# f28002x_dcsm_common_regs register map
Vendor: Texas Instruments
Peripheral module from a debugger description file (folder C2000).
Address unit: 16 bits
Registers are 32-bit, read-write, no defined reset value unless marked. A register's access mark holds for its fields unless they carry their own. Offsets are as the file gives them; lines under a group give offsets from that group; [hi:lo] are bit positions; {n}, {i} and the like mark numbered series; 'fields as' and 'values as' point back to an identical list; <NAME> marks a mode.

## DCSM_COMMON_REGS — DCSM COMMON Registers
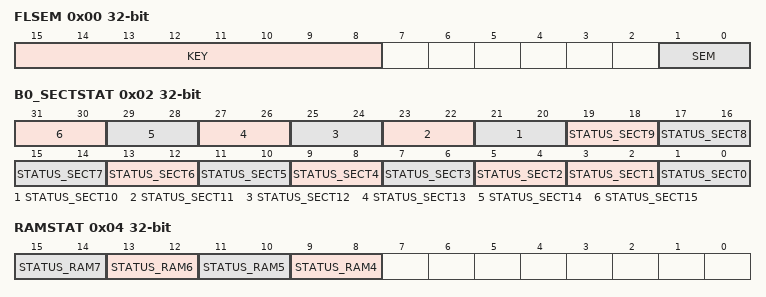
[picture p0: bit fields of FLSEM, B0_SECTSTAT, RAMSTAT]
0x00 FLSEM — Flash Wrapper Semaphore Register
  [15:8] KEY — Semaphore Key
  [1:0] SEM — Flash Semaphore Bit
0x02 B0_SECTSTAT ro — Flash BANK0 Sectors Status Register
  [2n+1:2n] STATUS_SECT{n} (n=9..15) — Zone Status Flash BANK0 Sector {n}
  [17:16] STATUS_SECT8 — Zone Status Flash BANK0 sector 8
  [2n+1:2n] STATUS_SECT{n} (n=2..7) — Zone Status Flash BANK0 Sector {n}
  [3:2] STATUS_SECT1 — Zone Status Flash BANK0 sector 1
  [1:0] STATUS_SECT0 — Zone Status Flash BANK0 Sector 0
0x04 RAMSTAT ro — RAM Status Register
  [2n+1:2n] STATUS_RAM{n} (n=4..7) — Zone Status RAM LS{n}
0x0A SECERRSTAT ro — Security Error Status Register
  [0] ERR — Security Configuration load Error Status
0x0C SECERRCLR — Security Error Clear Register
  [0] ERR — Clear Security Configuration Load Error Status Bit
0x0E SECERRFRC — Security Error Force Register
  [0] ERR — Set Security Configuration Load Error Status Bit
